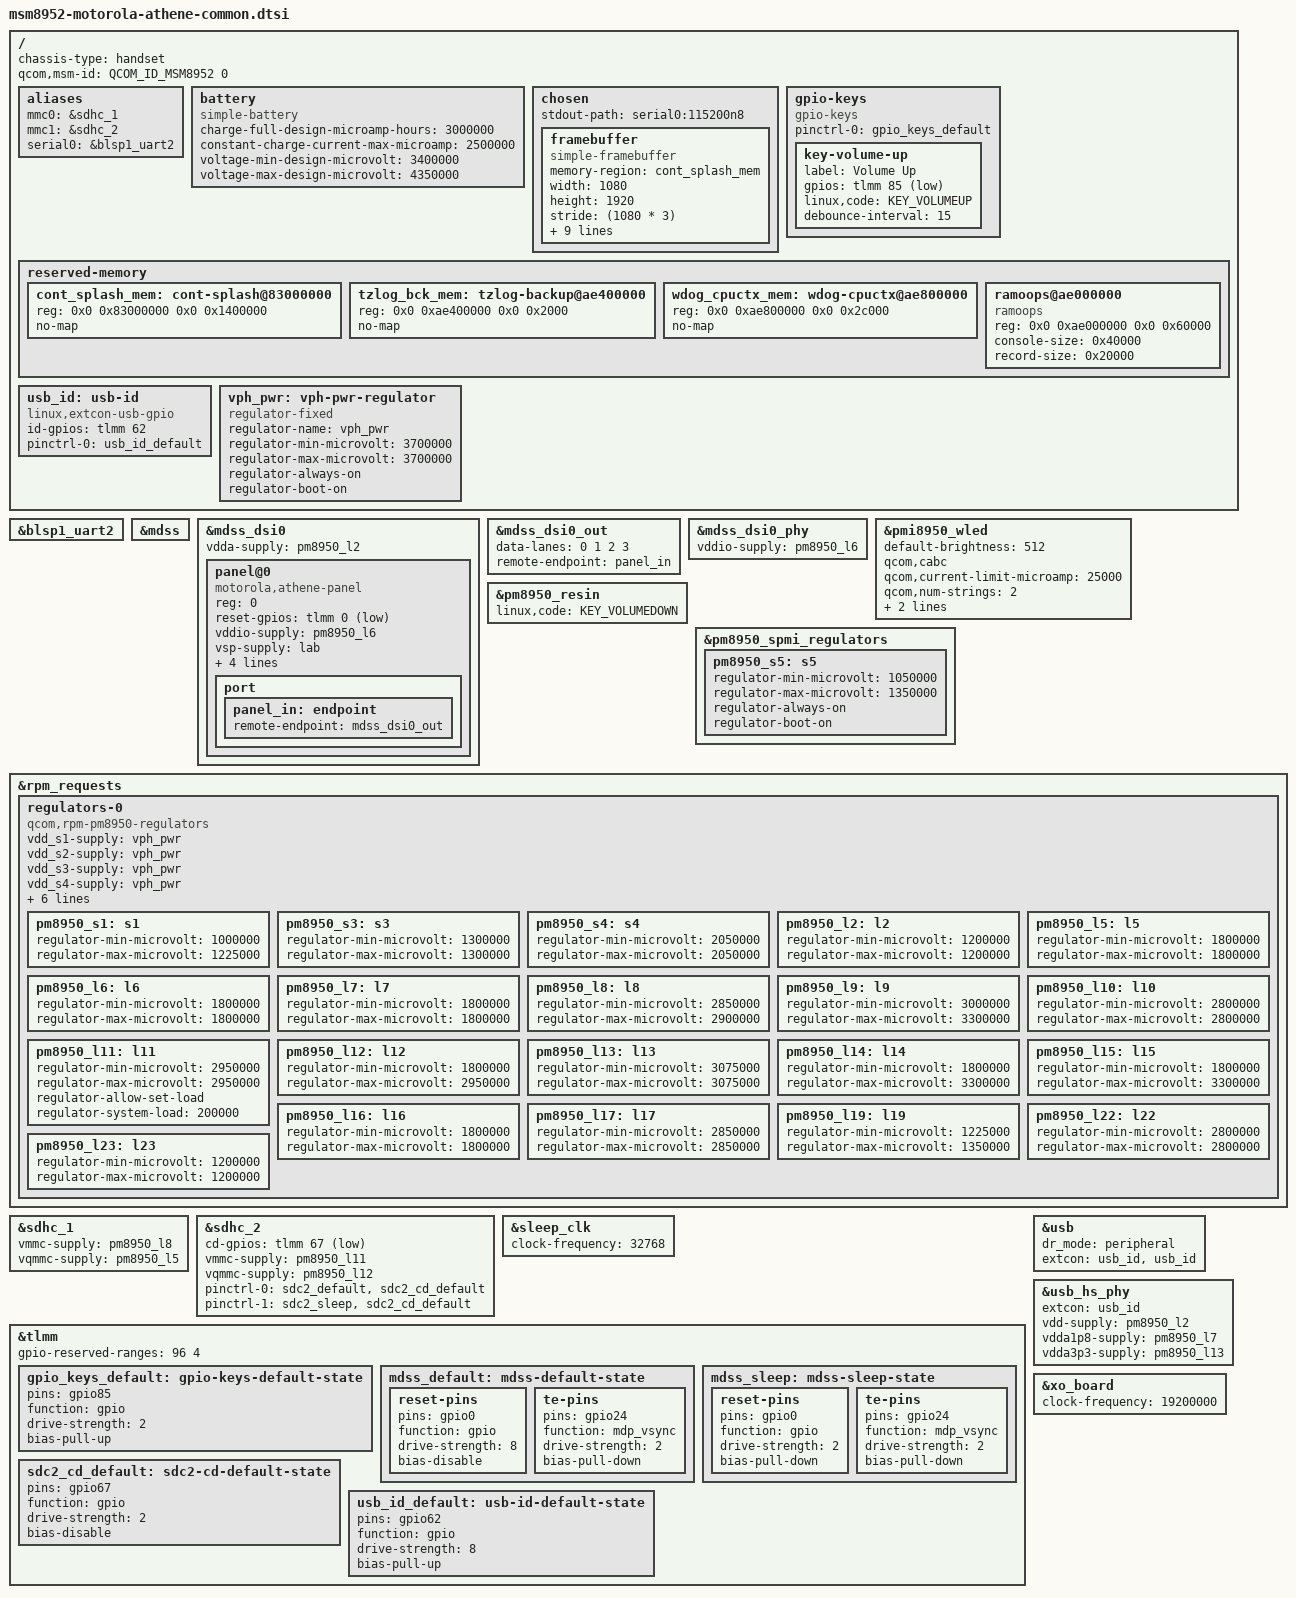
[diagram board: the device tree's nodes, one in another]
// SPDX-License-Identifier: GPL-2.0-only
/*
 * Copyright David Heidelberg <david@ixit.cz>
 *
 * Parts shared by all Motorola Moto G4 variants based on "athene".
 */

#include <dt-bindings/arm/qcom,ids.h>
#include <dt-bindings/gpio/gpio.h>
#include <dt-bindings/input/input.h>

#include "msm8952.dtsi"
#include "pm8950.dtsi"
#include "pmi8950.dtsi"

/ {
	chassis-type = "handset";

	qcom,msm-id = <QCOM_ID_MSM8952 0>;

	aliases {
		mmc0 = &sdhc_1;
		mmc1 = &sdhc_2;
		serial0 = &blsp1_uart2;
	};

	battery: battery {
		compatible = "simple-battery";

		charge-full-design-microamp-hours = <3000000>;
		constant-charge-current-max-microamp = <2500000>;
		voltage-min-design-microvolt = <3400000>;
		voltage-max-design-microvolt = <4350000>;
	};

	chosen {
		stdout-path = "serial0:115200n8";

		framebuffer {
			compatible = "simple-framebuffer";
			memory-region = <&cont_splash_mem>;

			width = <1080>;
			height = <1920>;
			stride = <(1080 * 3)>;
			format = "r8g8b8";

			power-domains = <&gcc MDSS_GDSC>;

			clocks = <&gcc GCC_MDSS_AHB_CLK>,
				 <&gcc GCC_MDSS_AXI_CLK>,
				 <&gcc GCC_MDSS_VSYNC_CLK>,
				 <&gcc GCC_MDSS_MDP_CLK>,
				 <&gcc GCC_MDSS_BYTE0_CLK>,
				 <&gcc GCC_MDSS_PCLK0_CLK>,
				 <&gcc GCC_MDSS_ESC0_CLK>;
		};
	};

	gpio-keys {
		compatible = "gpio-keys";

		pinctrl-0 = <&gpio_keys_default>;
		pinctrl-names = "default";

		key-volume-up {
			label = "Volume Up";
			gpios = <&tlmm 85 GPIO_ACTIVE_LOW>;
			linux,code = <KEY_VOLUMEUP>;
			debounce-interval = <15>;
		};
	};

	reserved-memory {
		cont_splash_mem: cont-splash@83000000 {
			reg = <0x0 0x83000000 0x0 0x1400000>;
			no-map;
		};

		/* The secure world writes to both of these on a watchdog bite */
		tzlog_bck_mem: tzlog-backup@ae400000 {
			reg = <0x0 0xae400000 0x0 0x2000>;
			no-map;
		};

		wdog_cpuctx_mem: wdog-cpuctx@ae800000 {
			reg = <0x0 0xae800000 0x0 0x2c000>;
			no-map;
		};

		/*
		 * The downstream kernel rounds its 0x3f800 record size down to
		 * 0x20000 and appends a 0x800 annotation zone at the end of the
		 * 0x80000 region, so its console zone sits at 0xae020000. Skip
		 * the annotation zone and use matching record and console sizes
		 * to place both zones where the stock kernel reads them back.
		 */
		ramoops@ae000000 {
			compatible = "ramoops";
			reg = <0x0 0xae000000 0x0 0x60000>;
			console-size = <0x40000>;
			record-size = <0x20000>;
		};
	};

	usb_id: usb-id {
		compatible = "linux,extcon-usb-gpio";
		id-gpios = <&tlmm 62 GPIO_ACTIVE_HIGH>;
		pinctrl-0 = <&usb_id_default>;
		pinctrl-names = "default";
	};

	vph_pwr: vph-pwr-regulator {
		compatible = "regulator-fixed";
		regulator-name = "vph_pwr";
		regulator-min-microvolt = <3700000>;
		regulator-max-microvolt = <3700000>;
		regulator-always-on;
		regulator-boot-on;
	};
};

&blsp1_uart2 {
	status = "okay";
};

&mdss {
	status = "okay";
};

&mdss_dsi0 {
	vdda-supply = <&pm8950_l2>;

	status = "okay";

	panel@0 {
		compatible = "motorola,athene-panel";
		reg = <0>;

		reset-gpios = <&tlmm 0 GPIO_ACTIVE_LOW>;

		vddio-supply = <&pm8950_l6>;
		vsp-supply = <&lab>;
		vsn-supply = <&ibb>;

		backlight = <&pmi8950_wled>;

		pinctrl-0 = <&mdss_default>;
		pinctrl-1 = <&mdss_sleep>;
		pinctrl-names = "default", "sleep";

		port {
			panel_in: endpoint {
				remote-endpoint = <&mdss_dsi0_out>;
			};
		};
	};
};

&mdss_dsi0_out {
	data-lanes = <0 1 2 3>;
	remote-endpoint = <&panel_in>;
};

&mdss_dsi0_phy {
	vddio-supply = <&pm8950_l6>;

	status = "okay";
};

&pmi8950_wled {
	default-brightness = <512>;

	qcom,cabc;
	qcom,current-limit-microamp = <25000>;
	qcom,num-strings = <2>;
	qcom,ovp-millivolt = <29500>;
	qcom,switching-freq = <800>;

	status = "okay";
};

&pm8950_resin {
	linux,code = <KEY_VOLUMEDOWN>;

	status = "okay";
};

&pm8950_spmi_regulators {
	/* APC */
	pm8950_s5: s5 {
		regulator-min-microvolt = <1050000>;
		regulator-max-microvolt = <1350000>;
		regulator-always-on;
		regulator-boot-on;
	};
};

&rpm_requests {
	regulators-0 {
		compatible = "qcom,rpm-pm8950-regulators";

		vdd_s1-supply = <&vph_pwr>;
		vdd_s2-supply = <&vph_pwr>;
		vdd_s3-supply = <&vph_pwr>;
		vdd_s4-supply = <&vph_pwr>;

		vdd_l1_l19-supply = <&pm8950_s3>;
		vdd_l2_l23-supply = <&pm8950_s3>;
		vdd_l3-supply = <&pm8950_s3>;
		vdd_l4_l5_l6_l7_l16-supply = <&pm8950_s4>;
		vdd_l8_l11_l12_l17_l22-supply = <&vph_pwr>;
		vdd_l9_l10_l13_l14_l15_l18-supply = <&vph_pwr>;

		pm8950_s1: s1 {
			regulator-min-microvolt = <1000000>;
			regulator-max-microvolt = <1225000>;
		};

		pm8950_s3: s3 {
			regulator-min-microvolt = <1300000>;
			regulator-max-microvolt = <1300000>;
		};

		pm8950_s4: s4 {
			regulator-min-microvolt = <2050000>;
			regulator-max-microvolt = <2050000>;
		};

		pm8950_l2: l2 {
			regulator-min-microvolt = <1200000>;
			regulator-max-microvolt = <1200000>;
		};

		pm8950_l5: l5 {
			regulator-min-microvolt = <1800000>;
			regulator-max-microvolt = <1800000>;
		};

		pm8950_l6: l6 {
			regulator-min-microvolt = <1800000>;
			regulator-max-microvolt = <1800000>;
		};

		pm8950_l7: l7 {
			regulator-min-microvolt = <1800000>;
			regulator-max-microvolt = <1800000>;
		};

		pm8950_l8: l8 {
			regulator-min-microvolt = <2850000>;
			regulator-max-microvolt = <2900000>;
		};

		pm8950_l9: l9 {
			regulator-min-microvolt = <3000000>;
			regulator-max-microvolt = <3300000>;
		};

		pm8950_l10: l10 {
			regulator-min-microvolt = <2800000>;
			regulator-max-microvolt = <2800000>;
		};

		pm8950_l11: l11 {
			regulator-min-microvolt = <2950000>;
			regulator-max-microvolt = <2950000>;
			regulator-allow-set-load;
			regulator-system-load = <200000>;
		};

		pm8950_l12: l12 {
			regulator-min-microvolt = <1800000>;
			regulator-max-microvolt = <2950000>;
		};

		pm8950_l13: l13 {
			regulator-min-microvolt = <3075000>;
			regulator-max-microvolt = <3075000>;
		};

		pm8950_l14: l14 {
			regulator-min-microvolt = <1800000>;
			regulator-max-microvolt = <3300000>;
		};

		pm8950_l15: l15 {
			regulator-min-microvolt = <1800000>;
			regulator-max-microvolt = <3300000>;
		};

		pm8950_l16: l16 {
			regulator-min-microvolt = <1800000>;
			regulator-max-microvolt = <1800000>;
		};

		pm8950_l17: l17 {
			regulator-min-microvolt = <2850000>;
			regulator-max-microvolt = <2850000>;
		};

		pm8950_l19: l19 {
			regulator-min-microvolt = <1225000>;
			regulator-max-microvolt = <1350000>;
		};

		pm8950_l22: l22 {
			regulator-min-microvolt = <2800000>;
			regulator-max-microvolt = <2800000>;
		};

		pm8950_l23: l23 {
			regulator-min-microvolt = <1200000>;
			regulator-max-microvolt = <1200000>;
		};
	};
};

&sdhc_1 {
	vmmc-supply = <&pm8950_l8>;
	vqmmc-supply = <&pm8950_l5>;

	status = "okay";
};

&sdhc_2 {
	cd-gpios = <&tlmm 67 GPIO_ACTIVE_LOW>;
	vmmc-supply = <&pm8950_l11>;
	vqmmc-supply = <&pm8950_l12>;
	pinctrl-0 = <&sdc2_default &sdc2_cd_default>;
	pinctrl-1 = <&sdc2_sleep &sdc2_cd_default>;
	pinctrl-names = "default", "sleep";

	status = "okay";
};

&sleep_clk {
	clock-frequency = <32768>;
};

&tlmm {
	/* 96-99: fingerprint reader (SPI) */
	gpio-reserved-ranges = <96 4>;

	gpio_keys_default: gpio-keys-default-state {
		pins = "gpio85";
		function = "gpio";
		drive-strength = <2>;
		bias-pull-up;
	};

	mdss_default: mdss-default-state {
		reset-pins {
			pins = "gpio0";
			function = "gpio";
			drive-strength = <8>;
			bias-disable;
		};

		te-pins {
			pins = "gpio24";
			function = "mdp_vsync";
			drive-strength = <2>;
			bias-pull-down;
		};
	};

	mdss_sleep: mdss-sleep-state {
		reset-pins {
			pins = "gpio0";
			function = "gpio";
			drive-strength = <2>;
			bias-pull-down;
		};

		te-pins {
			pins = "gpio24";
			function = "mdp_vsync";
			drive-strength = <2>;
			bias-pull-down;
		};
	};

	sdc2_cd_default: sdc2-cd-default-state {
		pins = "gpio67";
		function = "gpio";
		drive-strength = <2>;
		bias-disable;
	};

	usb_id_default: usb-id-default-state {
		pins = "gpio62";
		function = "gpio";
		drive-strength = <8>;
		bias-pull-up;
	};
};

&usb {
	dr_mode = "peripheral";
	extcon = <&usb_id>, <&usb_id>;

	status = "okay";
};

&usb_hs_phy {
	extcon = <&usb_id>;
	vdd-supply = <&pm8950_l2>;
	vdda1p8-supply = <&pm8950_l7>;
	vdda3p3-supply = <&pm8950_l13>;

	status = "okay";
};

&xo_board {
	clock-frequency = <19200000>;
};
